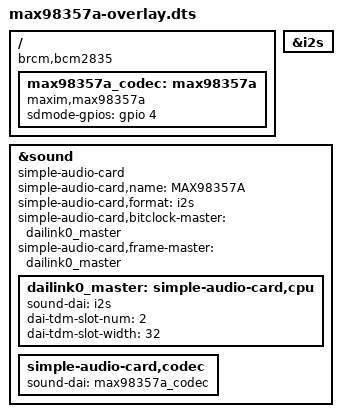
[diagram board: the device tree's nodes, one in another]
/dts-v1/;
/plugin/;

/ {
    compatible = "brcm,bcm2835";

    fragment@0 {
        target = <&i2s>;
        __overlay__ {
            status = "okay";
        };
    };

    fragment@1 {
        target-path = "/";
        __overlay__ {
            max98357a_codec: max98357a {
                #sound-dai-cells = <0>;
                compatible = "maxim,max98357a";
                sdmode-gpios = <&gpio 4 0>;
                status = "okay";
            };
        };
    };

    fragment@2 {
        target = <&sound>;
        __overlay__ {
            compatible = "simple-audio-card";
            simple-audio-card,name = "MAX98357A";
            simple-audio-card,format = "i2s";
            simple-audio-card,bitclock-master = <&dailink0_master>;
            simple-audio-card,frame-master = <&dailink0_master>;
            status = "okay";

            dailink0_master: simple-audio-card,cpu {
                sound-dai = <&i2s>;
                dai-tdm-slot-num = <2>;
                dai-tdm-slot-width = <32>;
            };

            simple-audio-card,codec {
                sound-dai = <&max98357a_codec>;
            };
        };
    };
};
